VERSION "created by canmatrix"

NS_ :

BS_:

BU_:

BO_ 100 Frame_With_Container: 16 Vector__XXX
 SG_ PDU_Contained_1_Signal1_905db81d : 7|8@0- (1,0) [-128|127] "" Vector__XXX
 SG_ PDU_Contained_1_Signal2_560dca45 : 15|16@0- (1,0) [-32768|32767] "" Vector__XXX
 SG_ PDU_Contained_1_Signal3_c2518f7b : 31|8@0- (1,0) [-128|127] "" Vector__XXX
 SG_ Contained_PDU_2_NewSignal_4521aa : 7|16@0- (1,0) [-32768|32767] "" Vector__XXX
 SG_ Contained_PDU_2_NewSignal_1_7013 : 23|16@0- (1,0) [-32768|32767] "" Vector__XXX
 SG_ PDU3_NewSignal_663edd1f1125ded2 : 7|8@0- (1,0) [-128|127] "" Vector__XXX

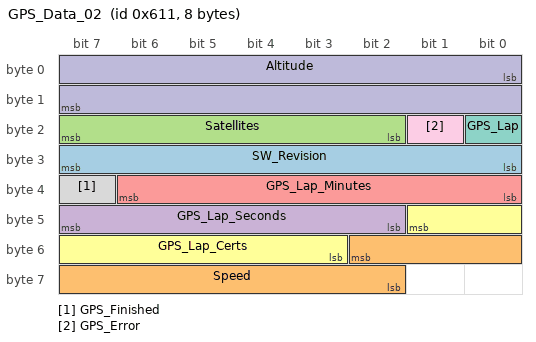
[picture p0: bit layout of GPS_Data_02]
BO_ 1553 GPS_Data_02: 8 Vector__XXX
 SG_ SW_Revision : 24|8@1- (1,0) [0|0] "" Vector__XXX
 SG_ Speed : 50|9@0- (1,0) [0|0] "" Vector__XXX
 SG_ Satellites : 18|6@1- (1,0) [0|0] "" Vector__XXX
 SG_ GPS_Lap_Seconds : 42|6@1- (1,0) [0|0] "" Vector__XXX
 SG_ GPS_Lap_Minutes : 32|7@1- (1,0) [0|0] "" Vector__XXX
 SG_ GPS_Lap_Certs : 41|7@0- (1,0) [0|0] "" Vector__XXX
 SG_ GPS_Lap : 16|1@1- (1,0) [0|0] "" Vector__XXX
 SG_ GPS_Finished : 39|1@1- (1,0) [0|0] "" Vector__XXX
 SG_ GPS_Error : 17|1@1- (1,0) [0|0] "" Vector__XXX
 SG_ Altitude : 0|16@1- (1,0) [0|0] "" Vector__XXX

BA_DEF_ BO_ "GenMsgSendType" ENUM  "cyclicX","spontanX","cyclicIfActiveX","spontanWithDelay","cyclicAndSpontanX","cyclicAndSpontanWithDelay","spontanWithRepitition","cyclicIfActiveAndSpontanWD","cyclicIfActiveFast","cyclicWithRepeatOnDemand","none";
BA_DEF_ BO_ "GenMsgStartValue" STRING;
BA_DEF_ SG_ "SystemSignalLongSymbol" STRING;

BA_ "GenMsgSendType" BO_ 100 1;
BA_ "GenMsgStartValue" BO_ 100 "00000000000000000000000000000000";

BA_ "SystemSignalLongSymbol" SG_ 100 PDU_Contained_1_Signal1_905db81d "PDU_Contained_1_Signal1_905db81da40081cb";
BA_ "SystemSignalLongSymbol" SG_ 100 PDU_Contained_1_Signal2_560dca45 "PDU_Contained_1_Signal2_560dca45b917ac81";
BA_ "SystemSignalLongSymbol" SG_ 100 PDU_Contained_1_Signal3_c2518f7b "PDU_Contained_1_Signal3_c2518f7b986c2257";
BA_ "SystemSignalLongSymbol" SG_ 100 Contained_PDU_2_NewSignal_4521aa "Contained_PDU_2_NewSignal_4521aa60e6ed341c";
BA_ "SystemSignalLongSymbol" SG_ 100 Contained_PDU_2_NewSignal_1_7013 "Contained_PDU_2_NewSignal_1_7013bc93a91870d1";
